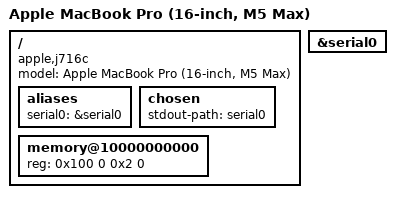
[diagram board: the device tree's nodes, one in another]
// SPDX-License-Identifier: GPL-2.0+ OR MIT
/*
 * Apple MacBook Pro (16-inch, M5 Max), Mac17,6 / J716c - DRAFT, untested.
 *
 * m1n1 (M4+ path) appends "idle=nop arm64.nowfxt" to bootargs and reserves
 * the secondary-core CTRR region itself.  Recommended extra first-boot
 * arguments: pd_ignore_unused clk_ignore_unused (PMGR table never validated).
 */

/dts-v1/;

#include "t6050.dtsi"

/ {
	compatible = "apple,j716c", "apple,t6050", "apple,arm-platform";
	model = "Apple MacBook Pro (16-inch, M5 Max)";

	aliases {
		serial0 = &serial0;
	};

	chosen {
		#address-cells = <2>;
		#size-cells = <2>;
		ranges;
		stdout-path = "serial0";
	};

	memory@10000000000 {
		device_type = "memory";
		reg = <0x100 0 0x2 0>; /* placeholder; m1n1 fills in the real map */
	};
};

&serial0 {
	status = "okay";
};
